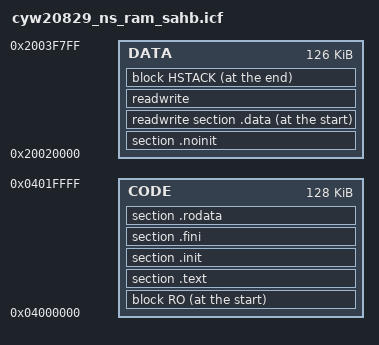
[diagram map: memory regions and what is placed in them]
/***************************************************************************//**
* \file cyw20829_ns
* \version 1.1
*
* Linker file for the IAR compiler.
*
*
********************************************************************************
* \copyright
* Copyright 2016-2020 Cypress Semiconductor Corporation
* SPDX-License-Identifier: Apache-2.0
*
* Licensed under the Apache License, Version 2.0 (the "License");
* you may not use this file except in compliance with the License.
* You may obtain a copy of the License at
*
*     http://www.apache.org/licenses/LICENSE-2.0
*
* Unless required by applicable law or agreed to in writing, software
* distributed under the License is distributed on an "AS IS" BASIS,
* WITHOUT WARRANTIES OR CONDITIONS OF ANY KIND, either express or implied.
* See the License for the specific language governing permissions and
* limitations under the License.
*******************************************************************************/

define memory mem with size = 4G;
define symbol CODE_ROM_S_SAHB_START = 0x10000000;
define symbol CODE_ROM_S_SAHB_SIZE = 0x00000000;
define symbol CODE_ROM_NS_SAHB_START = 0x00000000;
define symbol CODE_ROM_NS_SAHB_SIZE = 0x00000000;
define symbol CODE_SRAM0_S_SAHB_START = 0x30000000;
define symbol CODE_SRAM0_S_SAHB_SIZE = 0x00000000;
define symbol CODE_SRAM0_NS_SAHB_START = 0x20004200;
define symbol CODE_SRAM0_NS_SAHB_SIZE = 0x0001E000;
define symbol CODE_XIP_S_SAHB_START = 0x70000000;
define symbol CODE_XIP_S_SAHB_SIZE = 0x00000000;
define symbol CODE_XIP_NS_SAHB_START = 0x60000000;
define symbol CODE_XIP_NS_SAHB_SIZE = 0x08000000;

define symbol DATA_ROM_NS_SAHB_START = 0x00000000;
define symbol DATA_ROM_NS_SAHB_SIZE  = 0x00000000;
define symbol DATA_ROM_S_SAHB_START = 0x10000000;
define symbol DATA_ROM_S_SAHB_SIZE = 0x00000000;
define symbol BSS_ROM_NS_SAHB_START = 0x00000000;
define symbol BSS_ROM_NS_SAHB_SIZE = 0x00000000;
define symbol DATA_SRAM0_NS_SAHB_START = 0x20022200;
define symbol DATA_SRAM0_NS_SAHB_SIZE  = 0x0001DE00;
define symbol DATA_SRAM0_S_SAHB_START = 0x30000000;
define symbol DATA_SRAM0_S_SAHB_SIZE = 0x00000000;
define symbol BSS_SRAM0_NS_SAHB_START = 0x20000000;
define symbol BSS_SRAM0_NS_SAHB_SIZE = 0x00000000;
define symbol DATA_XIP_NS_SAHB_START = 0x60000000;
define symbol DATA_XIP_NS_SAHB_SIZE  = 0x00000000;
define symbol DATA_XIP_S_SAHB_START = 0x70000000;
define symbol DATA_XIP_S_SAHB_SIZE = 0x00000000;
define symbol BSS_XIP_NS_SAHB_START = 0x60000000;
define symbol BSS_XIP_NS_SAHB_SIZE = 0x00000000;

define symbol SRAM0_SIZE = 0x00040000;
define symbol CODE_NS_SRAM_START = 0x04000000;
define symbol SRAM0_NS_SAHB = 0x20000000;
define symbol CODE_NS_SRAM_SIZE = 0x00020000;
define symbol DATA_NS_SRAM_START = SRAM0_NS_SAHB+CODE_NS_SRAM_SIZE;
define symbol HEAP_SIZE = 0x0001000;
define symbol NS_MSP_STACK_SIZE = 0x0000800;
define symbol DATA_NS_SRAM_SIZE = SRAM0_SIZE-CODE_NS_SRAM_SIZE-NS_MSP_STACK_SIZE;
define symbol __size_cstack__ = 0x0000800;
define symbol __size_proc_stack__ = 0x0;
define symbol __size_heap__ = 0x0001000;

define region CODE = mem:[from CODE_NS_SRAM_START size CODE_NS_SRAM_SIZE];
define region DATA = mem:[from DATA_NS_SRAM_START size DATA_NS_SRAM_SIZE];
define block CSTACK with alignment = 8, size = __size_cstack__ { };
define block PROC_STACK with alignment = 8, size = __size_proc_stack__ { };
define block HEAP with expanding size, alignment = 8, minimum size = __size_heap__ { };
define block HSTACK {block HEAP, block PROC_STACK, last block CSTACK };
define block RO { first section NS_VECTOR, readonly };
initialize by copy { readwrite };
do not initialize  { section .noinit };

/*-Placement-*/
place at start of CODE  { block RO };
".text" : place in CODE { section .text };
".init" : place in CODE { section .init };
".fini" : place in CODE { section .fini };
".rodata" : place in CODE { section .rodata };
".noinit" : place in DATA { section .noinit };
place at start of DATA  { readwrite section .data};
place in DATA  { readwrite };
place at end of DATA  { block HSTACK };

